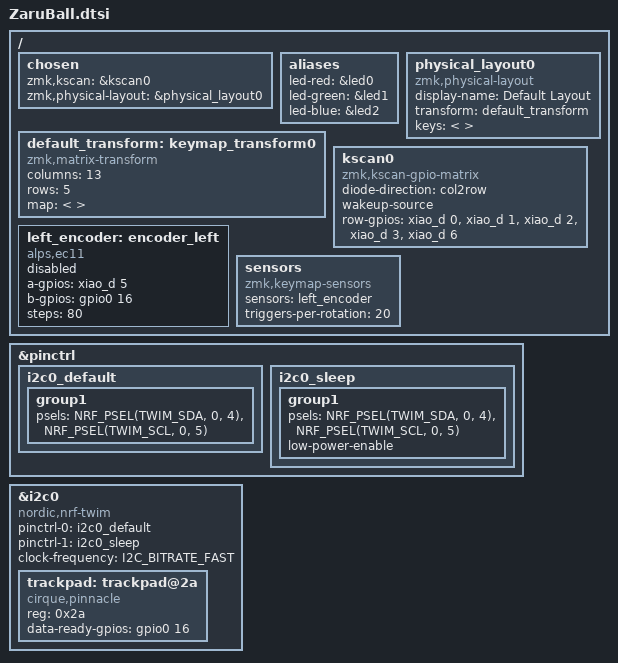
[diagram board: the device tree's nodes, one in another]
#include <dt-bindings/zmk/matrix_transform.h>
#include <physical_layouts.dtsi>
#include <zephyr/dt-bindings/input/input-event-codes.h>

/ {
    chosen {
        zmk,kscan = &kscan0;
        zmk,physical-layout = &physical_layout0;
    };

    /* LEDウィジェット用のエイリアス設定 (Xiao BLEの標準LEDを割り当て) */
    aliases {
        led-red = &led0;
        led-green = &led1;
        led-blue = &led2;
    };

    physical_layout0: physical_layout0 {
        compatible = "zmk,physical-layout";
        display-name = "Default Layout";
        transform = <&default_transform>;
        keys = <
            /* キーの物理レイアウト定義（中身は現在のものを維持してください） */
            /* ... (既存の key_physical_attrs の記述) ... */
        >;
    };

    default_transform: keymap_transform0 {
        compatible = "zmk,matrix-transform";
        columns = <13>;
        rows = <5>;
        map = <
            /* マトリックス変換（中身は現在のものを維持） */
            /* ... (既存の RC(x,y) の記述) ... */
        >;
    };

    kscan0: kscan0 {
        compatible = "zmk,kscan-gpio-matrix";
        diode-direction = "col2row";
        wakeup-source;
        row-gpios
            = <&xiao_d 0 (GPIO_ACTIVE_HIGH | GPIO_PULL_DOWN)>
            , <&xiao_d 1 (GPIO_ACTIVE_HIGH | GPIO_PULL_DOWN)>
            , <&xiao_d 2 (GPIO_ACTIVE_HIGH | GPIO_PULL_DOWN)>
            , <&xiao_d 3 (GPIO_ACTIVE_HIGH | GPIO_PULL_DOWN)>
            , <&xiao_d 6 (GPIO_ACTIVE_HIGH | GPIO_PULL_DOWN)>
            ;
    };

    left_encoder: encoder_left {
        compatible = "alps,ec11";
        a-gpios = <&xiao_d 5 (GPIO_ACTIVE_HIGH | GPIO_PULL_UP)>;
        b-gpios = <&gpio0 16 (GPIO_ACTIVE_HIGH | GPIO_PULL_UP)>;
        steps = <80>;
        status = "disabled";
    };

    sensors: sensors {
        compatible = "zmk,keymap-sensors";
        sensors = <&left_encoder>;
        triggers-per-rotation = <20>;
    };
};

/* I2Cピンの設定 */
&pinctrl {
    i2c0_default: i2c0_default {
        group1 {
            psels = <NRF_PSEL(TWIM_SDA, 0, 4)>,
                    <NRF_PSEL(TWIM_SCL, 0, 5)>;
        };
    };
    i2c0_sleep: i2c0_sleep {
        group1 {
            psels = <NRF_PSEL(TWIM_SDA, 0, 4)>,
                    <NRF_PSEL(TWIM_SCL, 0, 5)>;
            low-power-enable;
        };
    };
};

/* トラックパッド (Cirque) の設定 */
&i2c0 {
    status = "okay";
    compatible = "nordic,nrf-twim";
    pinctrl-0 = <&i2c0_default>;
    pinctrl-1 = <&i2c0_sleep>;
    pinctrl-names = "default", "sleep";
    clock-frequency = <I2C_BITRATE_FAST>;

    trackpad: trackpad@2a {
        compatible = "cirque,pinnacle";
        reg = <0x2a>;
        status = "okay";
        /* 最新のZMKでは data-ready-gpios を使用します */
        data-ready-gpios = <&gpio0 16 (GPIO_ACTIVE_HIGH)>;
    };
};
